# MCF5441x register map
Vendor: NXP; File version: 1.0
Registers are 32-bit, read-write, reset 0x0 unless marked. A register's access mark holds for its fields unless they carry their own. Offsets are from the block's base; [hi:lo] are bit positions; lines under a group give offsets from that group; {n}, {i} and the like mark numbered series.

## ESDHC
Base 0xFC0CC000
0x00 DSADDR
  [31:0] DS_ADDR
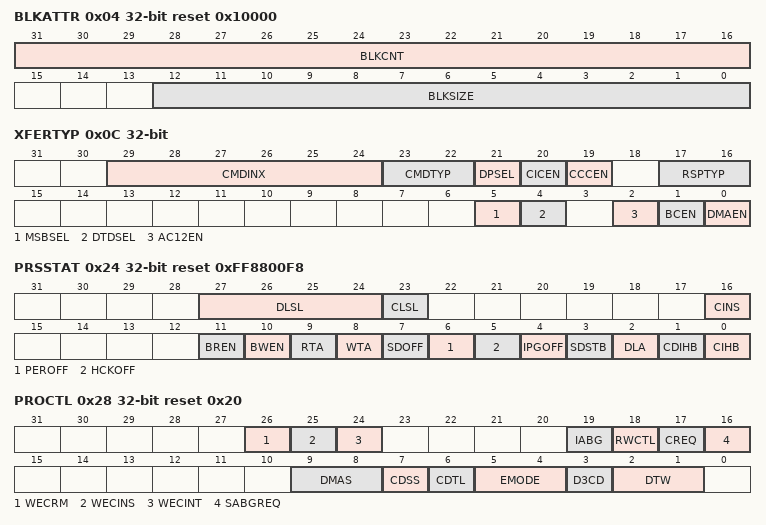
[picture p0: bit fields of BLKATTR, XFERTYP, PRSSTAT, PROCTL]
0x04 BLKATTR reset 0x10000
  [31:16] BLKCNT, [12:0] BLKSIZE
0x08 CMDARG
0x0C XFERTYP
  [29:24] CMDINX
  [23:22] CMDTYP
  [21] DPSEL
    0=NO_DATA_PRESENT; 1=DATA_PRESENT
  [20] CICEN
  [19] CCCEN
  [17:16] RSPTYP
  [5] MSBSEL
    0=SINGLE_BLOCK; 1=MULTIPLE_BLOCKS
  [4] DTDSEL
    0=WRITE_HOST_TO_CARD; 1=READ_CARD_TO_HOST
  [2] AC12EN
    0=DISABLE; 1=ENABLE
  [1] BCEN
    0=DISABLE; 1=ENABLE
  [0] DMAEN
    0=DISABLE; 1=ENABLE
{0x10+4i} CMDRSP{i} ro (i=0..3)
0x20 DATPORT
  [31:0] DATCONT read-modifies
0x24 PRSSTAT ro reset 0xFF8800F8
  [27:24] DLSL
  [23] CLSL
  [16] CINS
  [11] BREN
    0=DISABLE; 1=ENABLE
  [10] BWEN
    0=DISABLE; 1=ENABLE
  [9] RTA
    0=NO_VALID_DATA; 1=TRANSFERRING_DATA
  [8] WTA
    0=NO_VALID_DATA; 1=TRANSFERRING_DATA
  [7] SDOFF
    0=ACTIVE; 1=GATED_OFF
  [6] PEROFF
  [5] HCKOFF
  [4] IPGOFF
  [3] SDSTB
  [2] DLA
    0=INACTIVE; 1=ACTIVE
  [1] CDIHB
  [0] CIHB
0x28 PROCTL reset 0x20
  [26] WECRM
    0=DISABLE; 1=ENABLE
  [25] WECINS
    0=DISABLE; 1=ENABLE
  [24] WECINT
    0=DISABLE; 1=ENABLE
  [19] IABG
  [18] RWCTL
  [17] CREQ
    0=NO_EFFECT; 1=RESTART
  [16] SABGREQ
    0=TRANSFER; 1=STOP_OR_NOT_RESUME_YET
  [9:8] DMAS
    0=SIMPLE_DMA; 1=ADVANCED_DMA_1_ADMA1; 2=ADVANCED_DMA_2_ADMA2
  [7] CDSS
  [6] CDTL
    0=NO_CARD_IN_THE_SLOT; 1=CARD_IS_INSERTED
  [5:4] EMODE
  [3] D3CD
  [2:1] DTW
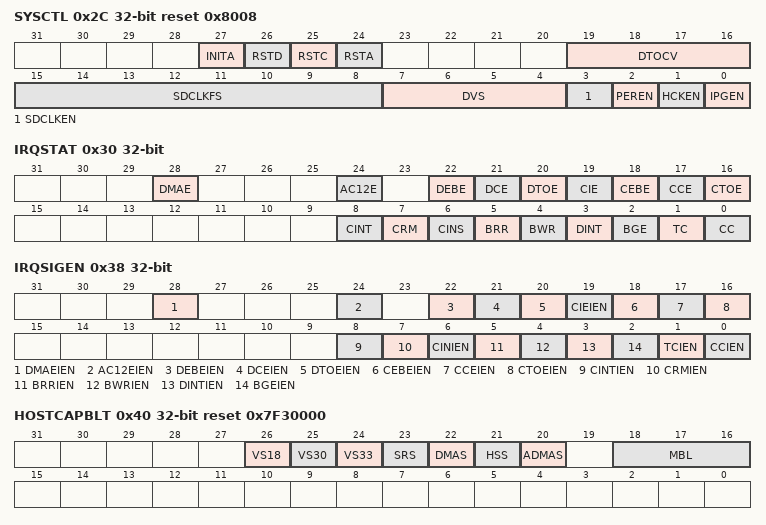
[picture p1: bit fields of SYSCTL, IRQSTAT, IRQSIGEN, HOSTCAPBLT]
0x2C SYSCTL reset 0x8008
  [27] INITA
  [26] RSTD
    0=WORK; 1=RESET
  [25] RSTC
    0=WORK; 1=RESET
  [24] RSTA
    0=WORK; 1=RESET
  [19:16] DTOCV
  [15:8] SDCLKFS
  [7:4] DVS
  [3] SDCLKEN
    0=DISABLED; 1=ENABLED
  [2] PEREN
  [1] HCKEN
  [0] IPGEN
0x30 IRQSTAT
  [28] DMAE write-1-clears
    0=NO_ERROR; 1=ERROR
  [24] AC12E write-1-clears
    0=NO_ERROR; 1=ERROR
  [22] DEBE write-1-clears
    0=NO_ERROR; 1=ERROR
  [21] DCE write-1-clears
    0=NO_ERROR; 1=ERROR
  [20] DTOE write-1-clears
    0=NO_ERROR; 1=TIMEOUT
  [19] CIE write-1-clears
    0=NO_ERROR; 1=TIMEOUT
  [18] CEBE write-1-clears
    0=NO_ERROR; 1=END_BIT_ERROR_GENERATED
  [17] CCE write-1-clears
    0=NO_ERROR; 1=CRC_ERROR_GENERATED
  [16] CTOE write-1-clears
    0=NO_ERROR; 1=TIME_OUT
  [8] CINT write-1-clears
    0=NO_CARD_INTERRUPT; 1=GENERATE_CARD_INTERRUPT
  [7] CRM write-1-clears
  [6] CINS write-1-clears
  [5] BRR write-1-clears
    0=NOT_READY_TO_READ_BUFFER; 1=READY_TO_READ_BUFFER
  [4] BWR write-1-clears
  [3] DINT write-1-clears
    0=NO_DMA_INTERRUPT; 1=DMA_INTERRUPT_IS_GENERATED
  [2] BGE write-1-clears
  [1] TC write-1-clears
  [0] CC write-1-clears
    0=NO_COMMAND_COMPLETE; 1=COMMAND_COMPLETE
0x34 IRQSTATEN reset 0x117F013F
0x38 IRQSIGEN
  [all] fields
    0=MASKED; 1=ENABLED
  [28] DMAEIEN
  [24] AC12EIEN
  [22] DEBEIEN
  [21] DCEIEN
  [20] DTOEIEN
  [19] CIEIEN
  [18] CEBEIEN
  [17] CCEIEN
  [16] CTOEIEN
  [8] CINTIEN
  [7] CRMIEN
  [6] CINIEN
  [5] BRRIEN
  [4] BWRIEN
  [3] DINTIEN
  [2] BGEIEN
  [1] TCIEN
  [0] CCIEN
0x3C AUTOC12ERR ro
0x40 HOSTCAPBLT ro reset 0x7F30000
  [26] VS18
  [25] VS30
  [24] VS33
  [23] SRS
    0=NOT_SUPPORTED; 1=SUPPORTED
  [22] DMAS
    0=NOT_SUPPORTED; 1=SUPPORTED
  [21] HSS
    0=NOT_SUPPORTED; 1=SUPPORTED
  [20] ADMAS
  [18:16] MBL
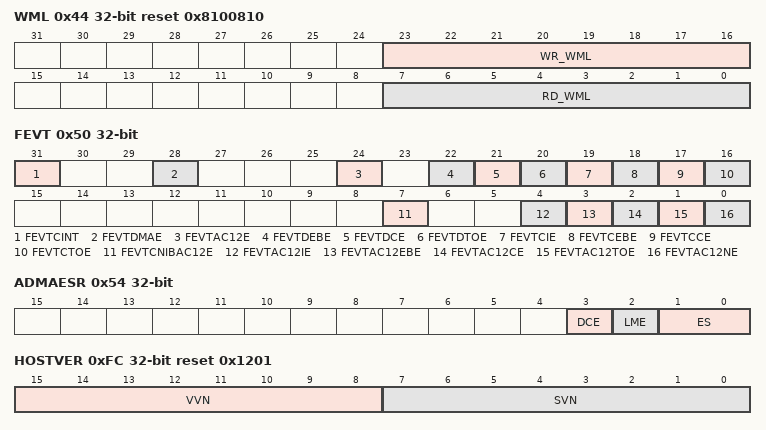
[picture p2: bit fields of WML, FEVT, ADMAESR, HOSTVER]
0x44 WML reset 0x8100810
  [23:16] WR_WML, [7:0] RD_WML
0x50 FEVT wo
  [31] FEVTCINT, [28] FEVTDMAE, [24] FEVTAC12E, [22] FEVTDEBE, [21] FEVTDCE, [20] FEVTDTOE, [19] FEVTCIE, [18] FEVTCEBE, [17] FEVTCCE, [16] FEVTCTOE, [7] FEVTCNIBAC12E, [4] FEVTAC12IE, [3] FEVTAC12EBE, [2] FEVTAC12CE, [1] FEVTAC12TOE, [0] FEVTAC12NE
0x54 ADMAESR ro
  [3] DCE
    0=NO_ERROR; 1=ERROR
  [2] LME
  [1:0] ES
0x58 ADMASAR
  [31:2] ADDR
0xC0 VENDOR reset 0x1
  [0] EXT_DMA_EN
0xFC HOSTVER ro reset 0x1201
  [15:8] VVN, [7:0] SVN

## ESW
Base 0xFC0DC000
0x00 REV ro reset not defined
0x04 SCR
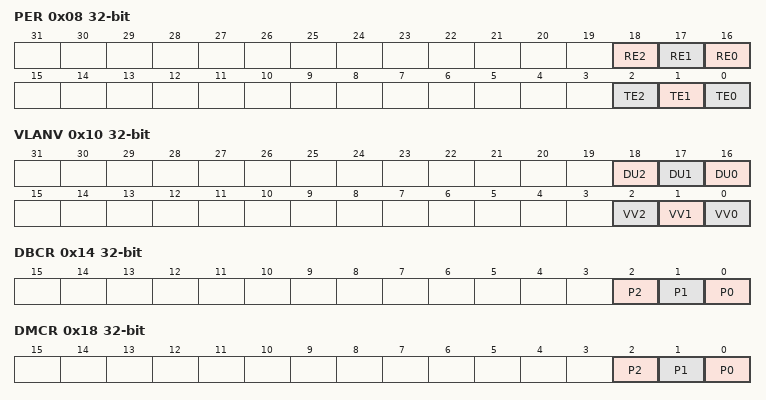
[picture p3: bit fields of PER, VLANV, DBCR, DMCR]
0x08 PER
  [18] RE2, [17] RE1, [16] RE0, [2] TE2, [1] TE1, [0] TE0
0x10 VLANV
  [18] DU2, [17] DU1, [16] DU0, [2] VV2, [1] VV1, [0] VV0
0x14 DBCR
  [2] P2, [1] P1, [0] P0
0x18 DMCR
  [2] P2, [1] P1, [0] P0
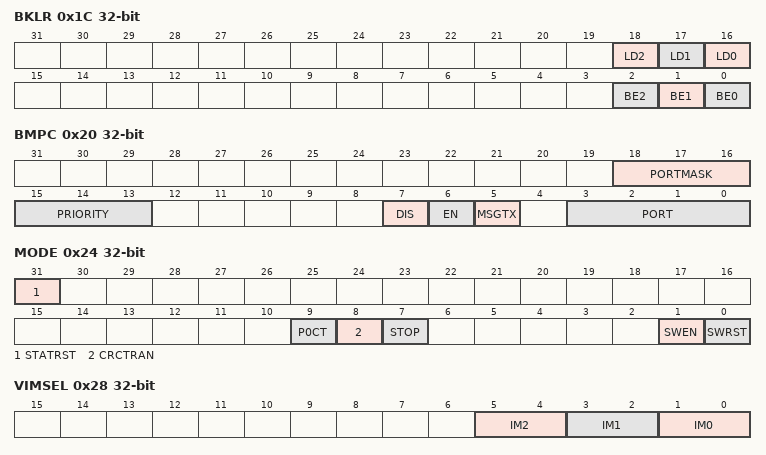
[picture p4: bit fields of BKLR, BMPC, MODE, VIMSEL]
0x1C BKLR
  [18] LD2, [17] LD1, [16] LD0, [2] BE2, [1] BE1, [0] BE0
0x20 BMPC
  [18:16] PORTMASK, [15:13] PRIORITY, [7] DIS, [6] EN, [5] MSGTX, [3:0] PORT
0x24 MODE
  [31] STATRST, [9] P0CT, [8] CRCTRAN, [7] STOP, [1] SWEN, [0] SWRST
0x28 VIMSEL
  [5:4] IM2, [3:2] IM1, [1:0] IM0
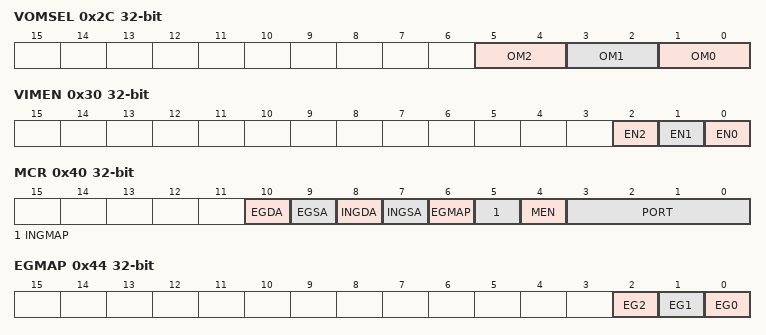
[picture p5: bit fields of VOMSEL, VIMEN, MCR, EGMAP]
0x2C VOMSEL
  [all] fields
    0=NO_OUTPUT_MANIPULATION; 1=MODE_1_STRIP_MODE; 2=MODE_2_TAG_THROUGH; 3=MODE_3_TRANSPARENT
  [5:4] OM2
  [3:2] OM1
  [1:0] OM0
0x30 VIMEN
  [2] EN2, [1] EN1, [0] EN0
0x34 VID reset 0x8100
  [31:0] TAG
0x40 MCR
  [10] EGDA
  [9] EGSA
  [8] INGDA
  [7] INGSA
  [6] EGMAP
  [5] INGMAP
  [4] MEN
    0=DISABLED; 1=ENABLED
  [3:0] PORT
0x44 EGMAP
  [2] EG2, [1] EG1, [0] EG0
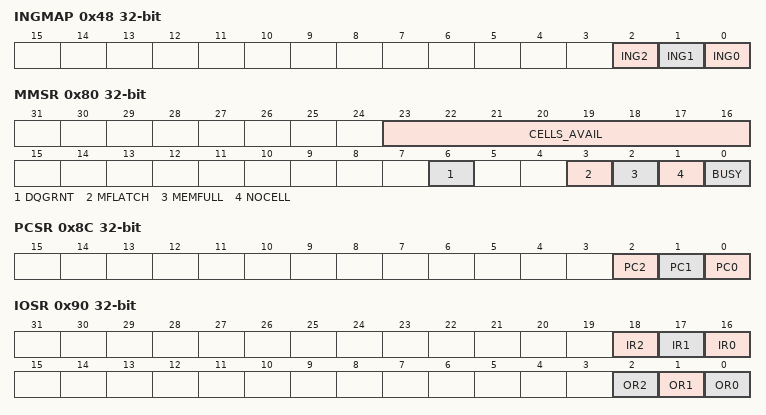
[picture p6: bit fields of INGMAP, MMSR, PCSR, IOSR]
0x48 INGMAP
  [2] ING2, [1] ING1, [0] ING0
0x4C INGSAL
  [31:0] ADDLOW
0x50 INGSAH
  [15:0] ADDHIGH
0x54 INGDAL
  [31:0] ADDLOW
0x58 INGDAH
  [15:0] ADDHIGH
0x5C EGSAL
  [31:0] ADDLOW
0x60 EGSAH
  [15:0] ADDHIGH
0x64 EGDAL
  [31:0] ADDLOW
0x68 EGDAH
  [15:0] ADDHIGH
0x6C MCVAL
  [7:0] COUNT
0x80 MMSR reset not defined
  [23:16] CELLS_AVAIL, [6] DQGRNT, [3] MFLATCH, [2] MEMFULL, [1] NOCELL, [0] BUSY
0x84 LMT reset 0x9
  [7:0] THRESH
0x88 LFC
  [31:0] COUNT
0x8C PCSR ro reset not defined
  [all] fields
    0=NOT_CONGESTED; 1=CONGESTED
  [2] PC2
  [1] PC1
  [0] PC0
0x90 IOSR ro reset not defined
  [18] IR2
    0=NOT_AVAILABLE; 1=DATA_AVAILABLE
  [17] IR1
    0=NOT_AVAILABLE; 1=DATA_AVAILABLE
  [16] IR0
    0=NOT_AVAILABLE; 1=DATA_AVAILABLE
  [2] OR2
    0=NOT_READY; 1=READY
  [1] OR1
    0=NOT_READY; 1=READY
  [0] OR0
    0=NOT_READY; 1=READY
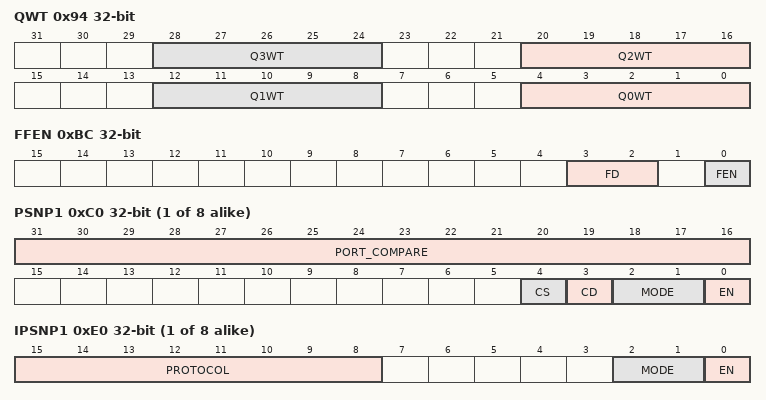
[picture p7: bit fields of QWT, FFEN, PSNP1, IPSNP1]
0x94 QWT
  [8n+4:8n] Q{n}WT (n=0..3)
0x9C P0BCT reset not defined
0xBC FFEN
  [3:2] FD, [0] FEN
{0xBC+4i} PSNP{i} (i=1..8)
  [31:16] PORT_COMPARE, [4] CS, [3] CD, [2:1] MODE, [0] EN
{0xDC+4i} IPSNP{i} (i=1..8)
  [15:8] PROTOCOL, [2:1] MODE, [0] EN
0x100 PVRES
  [23:0] PRIn
0x104 P1VRES reset not defined
  [23:0] PRIn
0x108 P2VRES reset not defined
  [23:0] PRIn
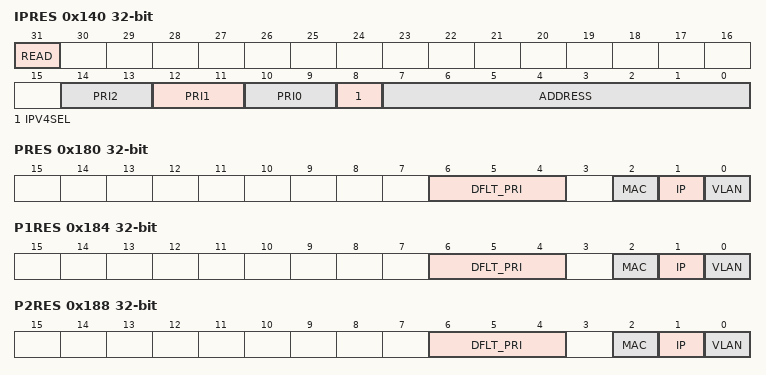
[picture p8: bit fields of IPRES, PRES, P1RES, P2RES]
0x140 IPRES
  [31] READ, [14:13] PRI2, [12:11] PRI1, [10:9] PRI0, [8] IPV4SEL, [7:0] ADDRESS
0x180 PRES
  [6:4] DFLT_PRI, [2] MAC, [1] IP, [0] VLAN
0x184 P1RES reset not defined
  [6:4] DFLT_PRI, [2] MAC, [1] IP, [0] VLAN
0x188 P2RES reset not defined
  [6:4] DFLT_PRI, [2] MAC, [1] IP, [0] VLAN
{0x200+4i} P{i}ID reset not defined (i=0..2)
  [15:0] VLANID
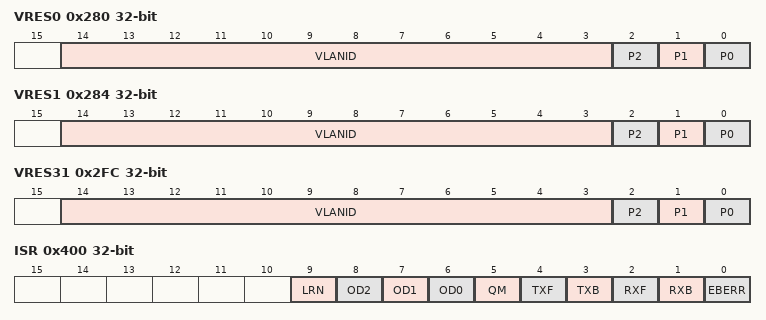
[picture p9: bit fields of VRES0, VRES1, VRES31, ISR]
0x280 VRES0
  [14:3] VLANID, [2] P2, [1] P1, [0] P0
0x284 VRES1
  [14:3] VLANID, [2] P2, [1] P1, [0] P0
{0x280+4i} VRES{i} (i=2..30)
0x2FC VRES31
  [14:3] VLANID, [2] P2, [1] P1, [0] P0
0x300 DISCN ro
0x304 DISCB ro
0x308 NDISCN ro
0x30C NDISCB ro
{0x310+0x10*i} P{i}OQC reset not defined (i=0..2)
{0x314+0x10*i} P{i}MVID reset not defined (i=0..2)
0x31C PBL ro
0x32C P1BL reset not defined
0x338 P0MVTAG reset not defined
0x33C P2BL reset not defined
0x400 ISR
  [9] LRN write-1-clears, [8] OD2 write-1-clears, [7] OD1 write-1-clears, [6] OD0 write-1-clears, [5] QM write-1-clears, [4] TXF write-1-clears, [3] TXB write-1-clears, [2] RXF write-1-clears, [1] RXB write-1-clears, [0] EBERR write-1-clears
0x404 IMR
0x408 RDSR
0x40C TDSR
0x410 MRBR
  [13:4] SIZE
0x414 RDAR
  [24] RDAR
0x418 TDAR
0x500 LREC0 ro
  [31:0] MAC_ADDR0
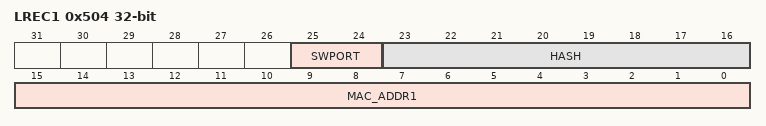
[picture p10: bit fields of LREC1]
0x504 LREC1 ro
  [25:24] SWPORT, [23:16] HASH, [15:0] MAC_ADDR1
0x508 LSR ro
  [0] DA
    0=INVALID; 1=VALID
{0x4000+8i} MAC_LOOKUP[{i}] (i=0..2047) group — MAC_LOOKUP[{i}]
  0x00 LOW reset not defined
  0x04 HIGH reset not defined
